# MINI51XAE_v1 register map
File version: 1.0
Registers are 32-bit, read-write, reset 0x0 unless marked. A register's access mark holds for its fields unless they carry their own. Offsets are from the block's base; [hi:lo] are bit positions; 'fields as' and 'values as' point back to an identical list.

## ACMP — ACMP Register Map
Base 0x400D0000
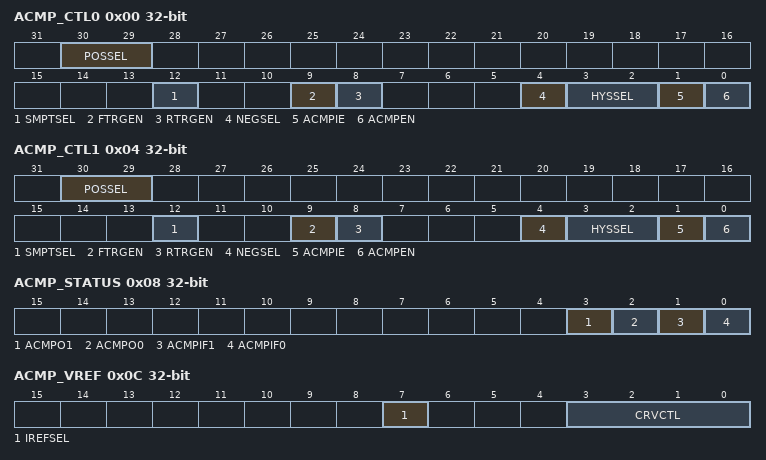
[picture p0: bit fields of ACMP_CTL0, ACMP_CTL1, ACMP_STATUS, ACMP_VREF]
0x00 ACMP_CTL0 — Analog Comparator 0 Control Register
  [30:29] POSSEL — Analog Comparator 0 Positive Input Selection
    0=CPP0 is from P1.5 pin; 1=CPP0 is from P1.0 pin; 2=CPP0 is from P1.2 pin; 3=CPP0 is from P1.3 pin
  [12] SMPTSEL — Analog Comparator 0 Speed Mode Selection
    0=Slow mode; 1=Fast mode
  [9] FTRGEN — Analog Comparator 0 Falling Edge Trigger Enable. Note: The bit is only effective while analog comparator 0 triggers PWM or Timer.
    0=Analog comparator 0 falling edge trigger PWM or Timer enabled; 1=Analog comparator 0 falling edge trigger disabled
  [8] RTRGEN — Analog Comparator 0 Rising Edge Trigger Enable. Note: The bit is only effective while analog comparator 0 triggers PWM or Timer.
    0=Analog comparator 0 rising edge trigger PWM or Timer enabled; 1=Analog comparator 0 rising edge trigger disabled
  [4] NEGSEL — Analog Comparator 0 Negative Input Selection
    0=The source of the negative comparator input is from CPN0 pin; 1=The source of the negative comparator input is from internal band-gap voltage or comparator reference voltage
  [3:2] HYSSEL — Analog Comparator 0 Hysteresis Selection
    0=CMP0 Hysteresis Disabled; 1=CMP0 Hysteresis typical range is 15mV; 2=CMP0 Hysteresis typical range is 90mV; 3=Same as 00
  [1] ACMPIE — Analog Comparator 0 Interrupt Enable Control
    0=Interrupt function Disabled; 1=Interrupt function Enabled
  [0] ACMPEN — Analog Comparator 0 Enable Control. Note: Analog comparator output needs to wait 2 us stable time after this bit is set.
    0=Analog Comparator 0 Disabled; 1=Analog Comparator 1 Enabled
0x04 ACMP_CTL1 — Analog Comparator 1 Control Register
  [30:29] POSSEL — Comparator 1 Positive Input Selection
    0=CPP1 is from P3.1 pin; 1=CPP1 is from P3.2 pin; 2=CPP1 is from P3.4 pin; 3=CPP1 is from P3.5 pin
  [12] SMPTSEL — Analog Comparator 1 Speed Mode Selection
    0=Slow mode; 1=Fast mode
  [9] FTRGEN — Analog Comparator 1 Falling Edge Trigger Enable. Note: The bit is only effective while analog comparator 1 triggers PWM or Timer.
    0=Analog comparator 1 falling edge trigger PWM or Timer enabled; 1=Analog comparator 1 falling edge trigger disabled
  [8] RTRGEN — Analog Comparator 1 Rising Edge Trigger Enable. Note: The bit is only effective while analog comparator 1 triggers PWM or Timer.
    0=Analog comparator 1 rising edge trigger PWM or Timer enabled; 1=Analog comparator 1 rising edge trigger disabled
  [4] NEGSEL — Analog Comparator 1 Negative Input Selection
    0=The source of the negative comparator input is from CPN1 pin; 1=The source of the negative comparator input is from internal band-gap voltage or comparator reference voltage
  [3:2] HYSSEL — Analog Comparator 1 Hysteresis Selction
    values as ACMP_CTL0.HYSSEL
  [1] ACMPIE — Analog Comparator 1 Interrupt Enable Control
    0=Interrupt function Disabled; 1=Interrupt function Enabled
  [0] ACMPEN — Analog Comparator 1 Enable Control. Note: Analog comparator output needs to wait 2 us stable time after this bit is set..
    0=Analog Comparator 1 Disabled; 1=Analog Comparator 1 Enabled
0x08 ACMP_STATUS — Analog Comparator 0/1 Status Register
  [3] ACMPO1 — Analog Comparator 1 Output
    0=Analog comparator 1 outputs 0; 1=Analog comparator 1 outputs 1
  [2] ACMPO0 — Analog Comparator 0 Output
    0=Analog comparator 0 outputs 0; 1=Analog comparator 0 outputs 1
  [1] ACMPIF1 — Analog Comparator 1 Flag. Note: Software can write 1 to clear this bit to zero.
    0=Analog comparator 1 output does not change; 1=Analog comparator 1 output changed
  [0] ACMPIF0 — Analog Comparator 0 Flag. Note: Software can write 1 to clear this bit to zero.
    0=Analog comparator 0 output does not change; 1=Analog comparator 0 output changed
0x0C ACMP_VREF — Analog Comparator Reference Voltage Control Register
  [7] IREFSEL — CRV Module Output Selection
    0=Band-gap voltage; 1=Internal comparator reference voltage
  [3:0] CRVCTL — Internal Reference Selection
